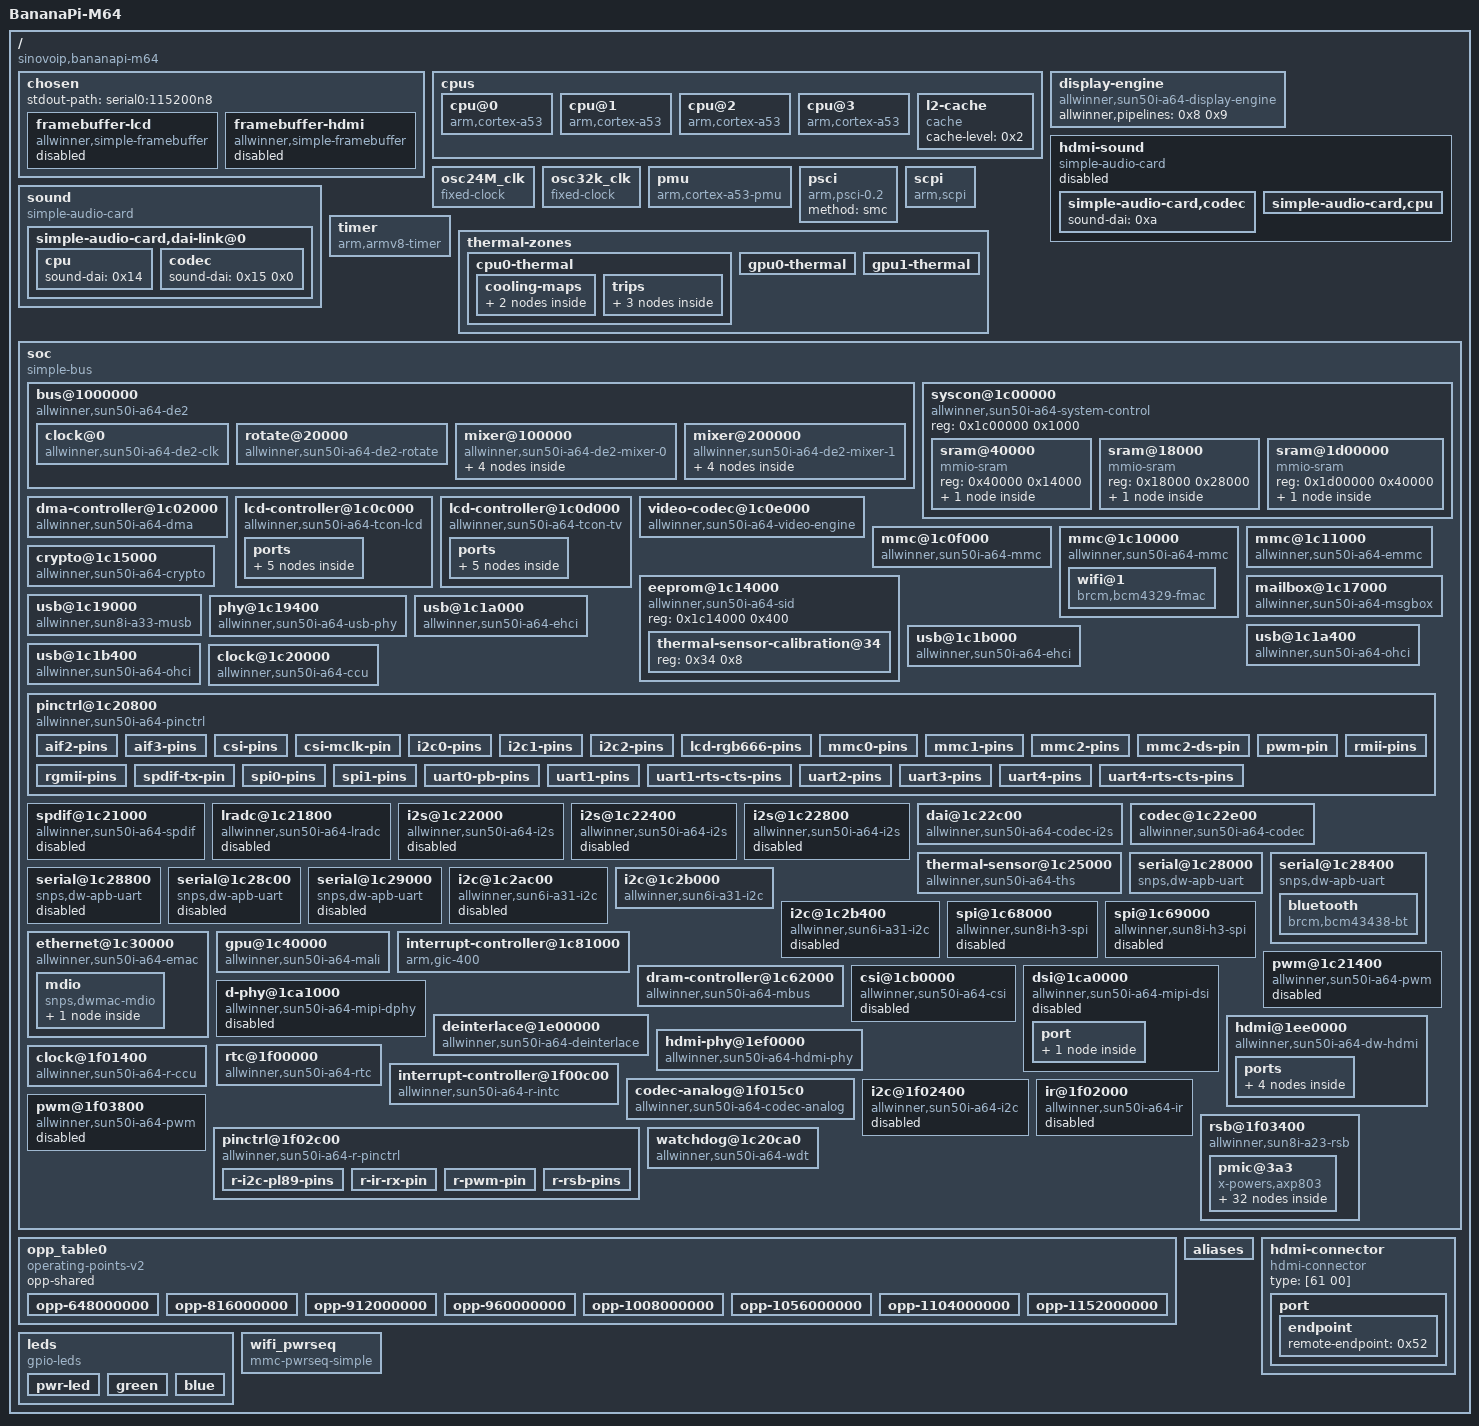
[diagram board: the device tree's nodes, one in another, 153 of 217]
/dts-v1/;

/ {
	interrupt-parent = <0x1>;
	#address-cells = <0x1>;
	#size-cells = <0x1>;
	model = "BananaPi-M64";
	compatible = "sinovoip,bananapi-m64", "allwinner,sun50i-a64";

	chosen {
		#address-cells = <0x1>;
		#size-cells = <0x1>;
		ranges;
		stdout-path = "serial0:115200n8";

		framebuffer-lcd {
			compatible = "allwinner,simple-framebuffer", "simple-framebuffer";
			allwinner,pipeline = "mixer0-lcd0";
			clocks = <0x2 0x64 0x3 0x6>;
			status = "disabled";
			phandle = <0x53>;
		};

		framebuffer-hdmi {
			compatible = "allwinner,simple-framebuffer", "simple-framebuffer";
			allwinner,pipeline = "mixer1-lcd1-hdmi";
			clocks = <0x3 0x7 0x2 0x65 0x2 0x6e>;
			status = "disabled";
			vcc-hdmi-supply = <0x4>;
			phandle = <0x54>;
		};
	};

	cpus {
		#address-cells = <0x1>;
		#size-cells = <0x0>;

		cpu@0 {
			compatible = "arm,cortex-a53";
			device_type = "cpu";
			reg = <0x0>;
			enable-method = "psci";
			next-level-cache = <0x5>;
			clocks = <0x2 0x15>;
			clock-names = "cpu";
			#cooling-cells = <0x2>;
			operating-points-v2 = <0x6>;
			cpu-supply = <0x7>;
			phandle = <0xc>;
		};

		cpu@1 {
			compatible = "arm,cortex-a53";
			device_type = "cpu";
			reg = <0x1>;
			enable-method = "psci";
			next-level-cache = <0x5>;
			clocks = <0x2 0x15>;
			clock-names = "cpu";
			#cooling-cells = <0x2>;
			operating-points-v2 = <0x6>;
			cpu-supply = <0x7>;
			phandle = <0xd>;
		};

		cpu@2 {
			compatible = "arm,cortex-a53";
			device_type = "cpu";
			reg = <0x2>;
			enable-method = "psci";
			next-level-cache = <0x5>;
			clocks = <0x2 0x15>;
			clock-names = "cpu";
			#cooling-cells = <0x2>;
			operating-points-v2 = <0x6>;
			cpu-supply = <0x7>;
			phandle = <0xe>;
		};

		cpu@3 {
			compatible = "arm,cortex-a53";
			device_type = "cpu";
			reg = <0x3>;
			enable-method = "psci";
			next-level-cache = <0x5>;
			clocks = <0x2 0x15>;
			clock-names = "cpu";
			#cooling-cells = <0x2>;
			operating-points-v2 = <0x6>;
			cpu-supply = <0x7>;
			phandle = <0xf>;
		};

		l2-cache {
			compatible = "cache";
			cache-level = <0x2>;
			phandle = <0x5>;
		};
	};

	display-engine {
		compatible = "allwinner,sun50i-a64-display-engine";
		allwinner,pipelines = <0x8 0x9>;
		status = "okay";
		phandle = <0x55>;
	};

	hdmi-sound {
		compatible = "simple-audio-card";
		simple-audio-card,format = "i2s";
		simple-audio-card,name = "sun50i-a64-hdmi";
		simple-audio-card,mclk-fs = <0x80>;
		simple-audio-card,frame-inversion;
		status = "disabled";
		phandle = <0x56>;

		simple-audio-card,codec {
			sound-dai = <0xa>;
		};

		simple-audio-card,cpu {
			sound-dai = <0xb>;
			dai-tdm-slot-num = <0x2>;
			dai-tdm-slot-width = <0x20>;
		};
	};

	osc24M_clk {
		#clock-cells = <0x0>;
		compatible = "fixed-clock";
		clock-frequency = <0x16e3600>;
		clock-output-names = "osc24M";
		phandle = <0x32>;
	};

	osc32k_clk {
		#clock-cells = <0x0>;
		compatible = "fixed-clock";
		clock-frequency = <0x8000>;
		clock-output-names = "ext-osc32k";
		phandle = <0x4c>;
	};

	pmu {
		compatible = "arm,cortex-a53-pmu";
		interrupts = <0x0 0x74 0x4 0x0 0x75 0x4 0x0 0x76 0x4 0x0 0x77 0x4>;
		interrupt-affinity = <0xc 0xd 0xe 0xf>;
	};

	psci {
		compatible = "arm,psci-0.2";
		method = "smc";
	};

	scpi {
		compatible = "arm,scpi";
		mboxes = <0x10 0x2 0x10 0x3>;
		mbox-names = "tx", "rx";
		shmem = <0x11>;
		phandle = <0x57>;
	};

	sound {
		#address-cells = <0x1>;
		#size-cells = <0x0>;
		compatible = "simple-audio-card";
		simple-audio-card,name = "sun50i-a64-audio";
		simple-audio-card,aux-devs = <0x12>;
		simple-audio-card,routing = "Headphone Jack", "HP", "Left DAC", "DAC Left", "Right DAC", "DAC Right", "ADC Left", "Left ADC", "ADC Right", "Right ADC", "MIC2", "Microphone Jack", "Onboard Microphone", "MBIAS", "MIC1", "Onboard Microphone";
		status = "okay";
		simple-audio-card,widgets = "Headphone", "Headphone Jack", "Microphone", "Microphone Jack", "Microphone", "Onboard Microphone";
		phandle = <0x58>;

		simple-audio-card,dai-link@0 {
			format = "i2s";
			frame-master = <0x13>;
			bitclock-master = <0x13>;
			mclk-fs = <0x80>;

			cpu {
				sound-dai = <0x14>;
				phandle = <0x13>;
			};

			codec {
				sound-dai = <0x15 0x0>;
				phandle = <0x59>;
			};
		};
	};

	timer {
		compatible = "arm,armv8-timer";
		allwinner,erratum-unknown1;
		arm,no-tick-in-suspend;
		interrupts = <0x1 0xd 0xf04 0x1 0xe 0xf04 0x1 0xb 0xf04 0x1 0xa 0xf04>;
	};

	thermal-zones {

		cpu0-thermal {
			polling-delay-passive = <0x0>;
			polling-delay = <0x0>;
			thermal-sensors = <0x16 0x0>;
			phandle = <0x5a>;

			cooling-maps {

				map0 {
					trip = <0x17>;
					cooling-device = <0xc 0xffffffff 0xffffffff 0xd 0xffffffff 0xffffffff 0xe 0xffffffff 0xffffffff 0xf 0xffffffff 0xffffffff>;
				};

				map1 {
					trip = <0x18>;
					cooling-device = <0xc 0xffffffff 0xffffffff 0xd 0xffffffff 0xffffffff 0xe 0xffffffff 0xffffffff 0xf 0xffffffff 0xffffffff>;
				};
			};

			trips {

				cpu_alert0 {
					temperature = <0x11170>;
					hysteresis = <0x7d0>;
					type = "passive";
					phandle = <0x17>;
				};

				cpu_alert1 {
					temperature = <0x13880>;
					hysteresis = <0x7d0>;
					type = "hot";
					phandle = <0x18>;
				};

				cpu_crit {
					temperature = <0x15f90>;
					hysteresis = <0x7d0>;
					type = "critical";
					phandle = <0x5b>;
				};
			};
		};

		gpu0-thermal {
			polling-delay-passive = <0x0>;
			polling-delay = <0x0>;
			thermal-sensors = <0x16 0x1>;
			phandle = <0x5c>;
		};

		gpu1-thermal {
			polling-delay-passive = <0x0>;
			polling-delay = <0x0>;
			thermal-sensors = <0x16 0x2>;
			phandle = <0x5d>;
		};
	};

	soc {
		compatible = "simple-bus";
		#address-cells = <0x1>;
		#size-cells = <0x1>;
		ranges;

		bus@1000000 {
			compatible = "allwinner,sun50i-a64-de2";
			reg = <0x1000000 0x400000>;
			allwinner,sram = <0x19 0x1>;
			#address-cells = <0x1>;
			#size-cells = <0x1>;
			ranges = <0x0 0x1000000 0x400000>;

			clock@0 {
				compatible = "allwinner,sun50i-a64-de2-clk";
				reg = <0x0 0x10000>;
				clocks = <0x2 0x34 0x2 0x63>;
				clock-names = "bus", "mod";
				resets = <0x2 0x1e>;
				#clock-cells = <0x1>;
				#reset-cells = <0x1>;
				phandle = <0x3>;
			};

			rotate@20000 {
				compatible = "allwinner,sun50i-a64-de2-rotate", "allwinner,sun8i-a83t-de2-rotate";
				reg = <0x20000 0x10000>;
				interrupts = <0x0 0x60 0x4>;
				clocks = <0x3 0x9 0x3 0xa>;
				clock-names = "bus", "mod";
				resets = <0x3 0x3>;
				phandle = <0x5e>;
			};

			mixer@100000 {
				compatible = "allwinner,sun50i-a64-de2-mixer-0";
				reg = <0x100000 0x100000>;
				clocks = <0x3 0x0 0x3 0x6>;
				clock-names = "bus", "mod";
				resets = <0x3 0x0>;
				phandle = <0x8>;

				ports {
					#address-cells = <0x1>;
					#size-cells = <0x0>;

					port@1 {
						#address-cells = <0x1>;
						#size-cells = <0x0>;
						reg = <0x1>;
						phandle = <0x5f>;

						endpoint@0 {
							reg = <0x0>;
							remote-endpoint = <0x1a>;
							phandle = <0x1e>;
						};

						endpoint@1 {
							reg = <0x1>;
							remote-endpoint = <0x1b>;
							phandle = <0x21>;
						};
					};
				};
			};

			mixer@200000 {
				compatible = "allwinner,sun50i-a64-de2-mixer-1";
				reg = <0x200000 0x100000>;
				clocks = <0x3 0x1 0x3 0x7>;
				clock-names = "bus", "mod";
				resets = <0x3 0x1>;
				phandle = <0x9>;

				ports {
					#address-cells = <0x1>;
					#size-cells = <0x0>;

					port@1 {
						#address-cells = <0x1>;
						#size-cells = <0x0>;
						reg = <0x1>;
						phandle = <0x60>;

						endpoint@0 {
							reg = <0x0>;
							remote-endpoint = <0x1c>;
							phandle = <0x1f>;
						};

						endpoint@1 {
							reg = <0x1>;
							remote-endpoint = <0x1d>;
							phandle = <0x22>;
						};
					};
				};
			};
		};

		syscon@1c00000 {
			compatible = "allwinner,sun50i-a64-system-control";
			reg = <0x1c00000 0x1000>;
			#address-cells = <0x1>;
			#size-cells = <0x1>;
			ranges;
			phandle = <0x3f>;

			sram@40000 {
				compatible = "mmio-sram";
				reg = <0x40000 0x14000>;
				#address-cells = <0x1>;
				#size-cells = <0x1>;
				ranges = <0x0 0x40000 0x14000>;
				phandle = <0x61>;

				scp-shmem@13c00 {
					compatible = "arm,scp-shmem";
					reg = <0x13c00 0x200>;
					phandle = <0x11>;
				};
			};

			sram@18000 {
				compatible = "mmio-sram";
				reg = <0x18000 0x28000>;
				#address-cells = <0x1>;
				#size-cells = <0x1>;
				ranges = <0x0 0x18000 0x28000>;
				phandle = <0x62>;

				sram-section@0 {
					compatible = "allwinner,sun50i-a64-sram-c";
					reg = <0x0 0x28000>;
					phandle = <0x19>;
				};
			};

			sram@1d00000 {
				compatible = "mmio-sram";
				reg = <0x1d00000 0x40000>;
				#address-cells = <0x1>;
				#size-cells = <0x1>;
				ranges = <0x0 0x1d00000 0x40000>;
				phandle = <0x63>;

				sram-section@0 {
					compatible = "allwinner,sun50i-a64-sram-c1", "allwinner,sun4i-a10-sram-c1";
					reg = <0x0 0x40000>;
					phandle = <0x24>;
				};
			};
		};

		dma-controller@1c02000 {
			compatible = "allwinner,sun50i-a64-dma";
			reg = <0x1c02000 0x1000>;
			interrupts = <0x0 0x32 0x4>;
			clocks = <0x2 0x1e>;
			dma-channels = <0x8>;
			dma-requests = <0x1b>;
			resets = <0x2 0x7>;
			#dma-cells = <0x1>;
			phandle = <0x34>;
		};

		lcd-controller@1c0c000 {
			compatible = "allwinner,sun50i-a64-tcon-lcd", "allwinner,sun8i-a83t-tcon-lcd";
			reg = <0x1c0c000 0x1000>;
			interrupts = <0x0 0x56 0x4>;
			clocks = <0x2 0x2f 0x2 0x64>;
			clock-names = "ahb", "tcon-ch0";
			clock-output-names = "tcon-pixel-clock";
			#clock-cells = <0x0>;
			resets = <0x2 0x18 0x2 0x23>;
			reset-names = "lcd", "lvds";
			phandle = <0x64>;

			ports {
				#address-cells = <0x1>;
				#size-cells = <0x0>;

				port@0 {
					#address-cells = <0x1>;
					#size-cells = <0x0>;
					reg = <0x0>;
					phandle = <0x65>;

					endpoint@0 {
						reg = <0x0>;
						remote-endpoint = <0x1e>;
						phandle = <0x1a>;
					};

					endpoint@1 {
						reg = <0x1>;
						remote-endpoint = <0x1f>;
						phandle = <0x1c>;
					};
				};

				port@1 {
					#address-cells = <0x1>;
					#size-cells = <0x0>;
					reg = <0x1>;
					phandle = <0x66>;

					endpoint@1 {
						reg = <0x1>;
						remote-endpoint = <0x20>;
						allwinner,tcon-channel = <0x1>;
						phandle = <0x46>;
					};
				};
			};
		};

		lcd-controller@1c0d000 {
			compatible = "allwinner,sun50i-a64-tcon-tv", "allwinner,sun8i-a83t-tcon-tv";
			reg = <0x1c0d000 0x1000>;
			interrupts = <0x0 0x57 0x4>;
			clocks = <0x2 0x30 0x2 0x65>;
			clock-names = "ahb", "tcon-ch1";
			resets = <0x2 0x19>;
			reset-names = "lcd";
			phandle = <0x67>;

			ports {
				#address-cells = <0x1>;
				#size-cells = <0x0>;

				port@0 {
					#address-cells = <0x1>;
					#size-cells = <0x0>;
					reg = <0x0>;
					phandle = <0x68>;

					endpoint@0 {
						reg = <0x0>;
						remote-endpoint = <0x21>;
						phandle = <0x1b>;
					};

					endpoint@1 {
						reg = <0x1>;
						remote-endpoint = <0x22>;
						phandle = <0x1d>;
					};
				};

				port@1 {
					#address-cells = <0x1>;
					#size-cells = <0x0>;
					reg = <0x1>;
					phandle = <0x69>;

					endpoint@1 {
						reg = <0x1>;
						remote-endpoint = <0x23>;
						phandle = <0x49>;
					};
				};
			};
		};

		video-codec@1c0e000 {
			compatible = "allwinner,sun50i-a64-video-engine";
			reg = <0x1c0e000 0x1000>;
			clocks = <0x2 0x2e 0x2 0x6a 0x2 0x5f>;
			clock-names = "ahb", "mod", "ram";
			resets = <0x2 0x17>;
			interrupts = <0x0 0x3a 0x4>;
			allwinner,sram = <0x24 0x1>;
		};

		mmc@1c0f000 {
			compatible = "allwinner,sun50i-a64-mmc";
			reg = <0x1c0f000 0x1000>;
			clocks = <0x2 0x1f 0x2 0x4b>;
			clock-names = "ahb", "mmc";
			resets = <0x2 0x8>;
			reset-names = "ahb";
			interrupts = <0x0 0x3c 0x4>;
			max-frequency = <0x8f0d180>;
			status = "okay";
			bus-width = <0x4>;
			#address-cells = <0x1>;
			#size-cells = <0x0>;
			pinctrl-names = "default";
			pinctrl-0 = <0x25>;
			vmmc-supply = <0x26>;
			cd-gpios = <0x27 0x5 0x6 0x1>;
			disable-wp;
			phandle = <0x6a>;
		};

		mmc@1c10000 {
			compatible = "allwinner,sun50i-a64-mmc";
			reg = <0x1c10000 0x1000>;
			clocks = <0x2 0x20 0x2 0x4c>;
			clock-names = "ahb", "mmc";
			resets = <0x2 0x9>;
			reset-names = "ahb";
			interrupts = <0x0 0x3d 0x4>;
			max-frequency = <0x8f0d180>;
			status = "okay";
			#address-cells = <0x1>;
			#size-cells = <0x0>;
			pinctrl-names = "default";
			pinctrl-0 = <0x28>;
			vmmc-supply = <0x29>;
			vqmmc-supply = <0x2a>;
			mmc-pwrseq = <0x2b>;
			bus-width = <0x4>;
			non-removable;
			phandle = <0x6b>;

			wifi@1 {
				reg = <0x1>;
				compatible = "brcm,bcm4329-fmac";
				interrupt-parent = <0x2c>;
				interrupts = <0x0 0x3 0x8>;
				interrupt-names = "host-wake";
				phandle = <0x6c>;
			};
		};

		mmc@1c11000 {
			compatible = "allwinner,sun50i-a64-emmc";
			reg = <0x1c11000 0x1000>;
			clocks = <0x2 0x21 0x2 0x4d>;
			clock-names = "ahb", "mmc";
			resets = <0x2 0xa>;
			reset-names = "ahb";
			interrupts = <0x0 0x3e 0x4>;
			max-frequency = <0xbebc200>;
			status = "okay";
			#address-cells = <0x1>;
			#size-cells = <0x0>;
			pinctrl-names = "default";
			pinctrl-0 = <0x2d 0x2e>;
			vmmc-supply = <0x26>;
			bus-width = <0x8>;
			non-removable;
			cap-mmc-hw-reset;
			phandle = <0x6d>;
		};

		eeprom@1c14000 {
			compatible = "allwinner,sun50i-a64-sid";
			reg = <0x1c14000 0x400>;
			#address-cells = <0x1>;
			#size-cells = <0x1>;
			phandle = <0x6e>;

			thermal-sensor-calibration@34 {
				reg = <0x34 0x8>;
				phandle = <0x36>;
			};
		};

		crypto@1c15000 {
			compatible = "allwinner,sun50i-a64-crypto";
			reg = <0x1c15000 0x1000>;
			interrupts = <0x0 0x5e 0x4>;
			clocks = <0x2 0x1d 0x2 0x4f>;
			clock-names = "bus", "mod";
			resets = <0x2 0x6>;
			phandle = <0x6f>;
		};

		mailbox@1c17000 {
			compatible = "allwinner,sun50i-a64-msgbox", "allwinner,sun6i-a31-msgbox";
			reg = <0x1c17000 0x1000>;
			clocks = <0x2 0x36>;
			resets = <0x2 0x20>;
			interrupts = <0x0 0x31 0x4>;
			#mbox-cells = <0x1>;
			phandle = <0x10>;
		};

		usb@1c19000 {
			compatible = "allwinner,sun8i-a33-musb";
			reg = <0x1c19000 0x400>;
			clocks = <0x2 0x29>;
			resets = <0x2 0x12>;
			interrupts = <0x0 0x47 0x4>;
			interrupt-names = "mc";
			phys = <0x2f 0x0>;
			phy-names = "usb";
			extcon = <0x2f 0x0>;
			dr_mode = "otg";
			status = "okay";
			phandle = <0x70>;
		};

		phy@1c19400 {
			compatible = "allwinner,sun50i-a64-usb-phy";
			reg = <0x1c19400 0x14 0x1c1a800 0x4 0x1c1b800 0x4>;
			reg-names = "phy_ctrl", "pmu0", "pmu1";
			clocks = <0x2 0x56 0x2 0x57>;
			clock-names = "usb0_phy", "usb1_phy";
			resets = <0x2 0x0 0x2 0x1>;
			reset-names = "usb0_reset", "usb1_reset";
			status = "okay";
			#phy-cells = <0x1>;
			usb0_id_det-gpios = <0x27 0x7 0x9 0x0>;
			usb0_vbus_power-supply = <0x30>;
			usb0_vbus-supply = <0x31>;
			phandle = <0x2f>;
		};

		usb@1c1a000 {
			compatible = "allwinner,sun50i-a64-ehci", "generic-ehci";
			reg = <0x1c1a000 0x100>;
			interrupts = <0x0 0x48 0x4>;
			clocks = <0x2 0x2c 0x2 0x2a 0x2 0x5b>;
			resets = <0x2 0x15 0x2 0x13>;
			status = "okay";
			phandle = <0x71>;
		};

		usb@1c1a400 {
			compatible = "allwinner,sun50i-a64-ohci", "generic-ohci";
			reg = <0x1c1a400 0x100>;
			interrupts = <0x0 0x49 0x4>;
			clocks = <0x2 0x2c 0x2 0x5b>;
			resets = <0x2 0x15>;
			status = "okay";
			phandle = <0x72>;
		};

		usb@1c1b000 {
			compatible = "allwinner,sun50i-a64-ehci", "generic-ehci";
			reg = <0x1c1b000 0x100>;
			interrupts = <0x0 0x4a 0x4>;
			clocks = <0x2 0x2d 0x2 0x2b 0x2 0x5d>;
			resets = <0x2 0x16 0x2 0x14>;
			phys = <0x2f 0x1>;
			phy-names = "usb";
			status = "okay";
			phandle = <0x73>;
		};

		usb@1c1b400 {
			compatible = "allwinner,sun50i-a64-ohci", "generic-ohci";
			reg = <0x1c1b400 0x100>;
			interrupts = <0x0 0x4b 0x4>;
			clocks = <0x2 0x2d 0x2 0x5d>;
			resets = <0x2 0x16>;
			phys = <0x2f 0x1>;
			phy-names = "usb";
			status = "okay";
			phandle = <0x74>;
		};

		clock@1c20000 {
			compatible = "allwinner,sun50i-a64-ccu";
			reg = <0x1c20000 0x400>;
			clocks = <0x32 0x33 0x0>;
			clock-names = "hosc", "losc";
			protected-clocks = <0x36>;
			#clock-cells = <0x1>;
			#reset-cells = <0x1>;
			phandle = <0x2>;
		};

		pinctrl@1c20800 {
			compatible = "allwinner,sun50i-a64-pinctrl";
			reg = <0x1c20800 0x400>;
			interrupts = <0x0 0xb 0x4 0x0 0x11 0x4 0x0 0x15 0x4>;
			clocks = <0x2 0x3a 0x32 0x33 0x0>;
			clock-names = "apb", "hosc", "losc";
			gpio-controller;
			#gpio-cells = <0x3>;
			interrupt-controller;
			#interrupt-cells = <0x3>;
			phandle = <0x27>;

			aif2-pins {
				pins = "PB4", "PB5", "PB6", "PB7";
				function = "aif2";
				phandle = <0x75>;
			};

			aif3-pins {
				pins = "PG10", "PG11", "PG12", "PG13";
				function = "aif3";
				phandle = <0x76>;
			};

			csi-pins {
				pins = "PE0", "PE2", "PE3", "PE4", "PE5", "PE6", "PE7", "PE8", "PE9", "PE10", "PE11";
				function = "csi";
				phandle = <0x44>;
			};

			csi-mclk-pin {
				pins = "PE1";
				function = "csi";
				phandle = <0x77>;
			};

			i2c0-pins {
				pins = "PH0", "PH1";
				function = "i2c0";
				phandle = <0x3a>;
			};

			i2c1-pins {
				pins = "PH2", "PH3";
				function = "i2c1";
				bias-pull-up;
				phandle = <0x3b>;
			};

			i2c2-pins {
				pins = "PE14", "PE15";
				function = "i2c2";
				phandle = <0x3c>;
			};

			lcd-rgb666-pins {
				pins = "PD0", "PD1", "PD2", "PD3", "PD4", "PD5", "PD6", "PD7", "PD8", "PD9", "PD10", "PD11", "PD12", "PD13", "PD14", "PD15", "PD16", "PD17", "PD18", "PD19", "PD20", "PD21";
				function = "lcd0";
				phandle = <0x78>;
			};

			mmc0-pins {
				pins = "PF0", "PF1", "PF2", "PF3", "PF4", "PF5";
				function = "mmc0";
				drive-strength = <0x1e>;
				bias-pull-up;
				phandle = <0x25>;
			};

			mmc1-pins {
				pins = "PG0", "PG1", "PG2", "PG3", "PG4", "PG5";
				function = "mmc1";
				drive-strength = <0x1e>;
				bias-pull-up;
				phandle = <0x28>;
			};

			mmc2-pins {
				pins = "PC5", "PC6", "PC8", "PC9", "PC10", "PC11", "PC12", "PC13", "PC14", "PC15", "PC16";
				function = "mmc2";
				drive-strength = <0x1e>;
				bias-pull-up;
				phandle = <0x2d>;
			};

			mmc2-ds-pin {
				pins = "PC1";
				function = "mmc2";
				drive-strength = <0x1e>;
				bias-pull-up;
				phandle = <0x2e>;
			};

			pwm-pin {
				pins = "PD22";
				function = "pwm";
				phandle = <0x43>;
			};

			rmii-pins {
				pins = "PD10", "PD11", "PD13", "PD14", "PD17", "PD18", "PD19", "PD20", "PD22", "PD23";
				function = "emac";
				drive-strength = <0x28>;
				phandle = <0x79>;
			};

			rgmii-pins {
				pins = "PD8", "PD9", "PD10", "PD11", "PD12", "PD13", "PD15", "PD16", "PD17", "PD18", "PD19", "PD20", "PD21", "PD22", "PD23";
				function = "emac";
				drive-strength = <0x28>;
				phandle = <0x40>;
			};

			spdif-tx-pin {
				pins = "PH8";
				function = "spdif";
				phandle = <0x35>;
			};

			spi0-pins {
				pins = "PC0", "PC1", "PC2", "PC3";
				function = "spi0";
				phandle = <0x3d>;
			};

			spi1-pins {
				pins = "PD0", "PD1", "PD2", "PD3";
				function = "spi1";
				phandle = <0x3e>;
			};

			uart0-pb-pins {
				pins = "PB8", "PB9";
				function = "uart0";
				phandle = <0x37>;
			};

			uart1-pins {
				pins = "PG6", "PG7";
				function = "uart1";
				phandle = <0x38>;
			};

			uart1-rts-cts-pins {
				pins = "PG8", "PG9";
				function = "uart1";
				phandle = <0x39>;
			};

			uart2-pins {
				pins = "PB0", "PB1";
				function = "uart2";
				phandle = <0x7a>;
			};

			uart3-pins {
				pins = "PD0", "PD1";
				function = "uart3";
				phandle = <0x7b>;
			};

			uart4-pins {
				pins = "PD2", "PD3";
				function = "uart4";
				phandle = <0x7c>;
			};

			uart4-rts-cts-pins {
				pins = "PD4", "PD5";
				function = "uart4";
				phandle = <0x7d>;
			};
		};

		spdif@1c21000 {
			#sound-dai-cells = <0x0>;
			compatible = "allwinner,sun50i-a64-spdif", "allwinner,sun8i-h3-spdif";
			reg = <0x1c21000 0x400>;
			interrupts = <0x0 0xc 0x4>;
			clocks = <0x2 0x39 0x2 0x55>;
			resets = <0x2 0x25>;
			clock-names = "apb", "spdif";
			dmas = <0x34 0x2>;
			dma-names = "tx";
			pinctrl-names = "default";
			pinctrl-0 = <0x35>;
			status = "disabled";
			phandle = <0x7e>;
		};

		lradc@1c21800 {
			compatible = "allwinner,sun50i-a64-lradc", "allwinner,sun4i-a10-lradc-keys";
			reg = <0x1c21800 0x400>;
			interrupts = <0x0 0x1e 0x4>;
			status = "disabled";
			phandle = <0x7f>;
		};

		i2s@1c22000 {
			#sound-dai-cells = <0x0>;
			compatible = "allwinner,sun50i-a64-i2s", "allwinner,sun8i-h3-i2s";
			reg = <0x1c22000 0x400>;
			interrupts = <0x0 0xd 0x4>;
			clocks = <0x2 0x3c 0x2 0x52>;
			clock-names = "apb", "mod";
			resets = <0x2 0x27>;
			dma-names = "rx", "tx";
			dmas = <0x34 0x3 0x34 0x3>;
			status = "disabled";
			phandle = <0x80>;
		};

		i2s@1c22400 {
			#sound-dai-cells = <0x0>;
			compatible = "allwinner,sun50i-a64-i2s", "allwinner,sun8i-h3-i2s";
			reg = <0x1c22400 0x400>;
			interrupts = <0x0 0xe 0x4>;
			clocks = <0x2 0x3d 0x2 0x53>;
			clock-names = "apb", "mod";
			resets = <0x2 0x28>;
			dma-names = "rx", "tx";
			dmas = <0x34 0x4 0x34 0x4>;
			status = "disabled";
			phandle = <0x81>;
		};

		i2s@1c22800 {
			#sound-dai-cells = <0x0>;
			compatible = "allwinner,sun50i-a64-i2s", "allwinner,sun8i-h3-i2s";
			reg = <0x1c22800 0x400>;
			interrupts = <0x0 0xf 0x4>;
			clocks = <0x2 0x3e 0x2 0x54>;
			clock-names = "apb", "mod";
			resets = <0x2 0x29>;
			dma-names = "tx";
			dmas = <0x34 0x1b>;
			allwinner,playback-channels = <0x8>;
			status = "disabled";
			phandle = <0xb>;
		};

		dai@1c22c00 {
			#sound-dai-cells = <0x0>;
			compatible = "allwinner,sun50i-a64-codec-i2s";
			reg = <0x1c22c00 0x200>;
			interrupts = <0x0 0x1d 0x4>;
			clocks = <0x2 0x38 0x2 0x6b>;
			clock-names = "apb", "mod";
			resets = <0x2 0x24>;
			dmas = <0x34 0xf 0x34 0xf>;
			dma-names = "rx", "tx";
			status = "okay";
			phandle = <0x14>;
		};

		codec@1c22e00 {
			#sound-dai-cells = <0x1>;
			compatible = "allwinner,sun50i-a64-codec";
			reg = <0x1c22e00 0x600>;
			interrupts = <0x0 0x1c 0x4>;
			clocks = <0x2 0x38 0x2 0x6b>;
			clock-names = "bus", "mod";
			status = "okay";
			phandle = <0x15>;
		};

		thermal-sensor@1c25000 {
			compatible = "allwinner,sun50i-a64-ths";
			reg = <0x1c25000 0x100>;
			clocks = <0x2 0x3b 0x2 0x49>;
			clock-names = "bus", "mod";
			interrupts = <0x0 0x1f 0x4>;
			resets = <0x2 0x26>;
			nvmem-cells = <0x36>;
			nvmem-cell-names = "calibration";
			#thermal-sensor-cells = <0x1>;
			phandle = <0x16>;
		};

		serial@1c28000 {
			compatible = "snps,dw-apb-uart";
			reg = <0x1c28000 0x400>;
			interrupts = <0x0 0x0 0x4>;
			reg-shift = <0x2>;
			reg-io-width = <0x4>;
			fifo-size = <0x40>;
			clocks = <0x2 0x43>;
			resets = <0x2 0x2e>;
			status = "okay";
			pinctrl-names = "default";
			pinctrl-0 = <0x37>;
			phandle = <0x82>;
		};

		serial@1c28400 {
			compatible = "snps,dw-apb-uart";
			reg = <0x1c28400 0x400>;
			interrupts = <0x0 0x1 0x4>;
			reg-shift = <0x2>;
			reg-io-width = <0x4>;
			fifo-size = <0x40>;
			clocks = <0x2 0x44>;
			resets = <0x2 0x2f>;
			status = "okay";
			pinctrl-names = "default";
			pinctrl-0 = <0x38 0x39>;
			uart-has-rtscts;
			phandle = <0x83>;

			bluetooth {
				compatible = "brcm,bcm43438-bt";
				clocks = <0x33 0x1>;
				clock-names = "lpo";
				vbat-supply = <0x29>;
				vddio-supply = <0x2a>;
				device-wakeup-gpios = <0x2c 0x0 0x6 0x0>;
				host-wakeup-gpios = <0x2c 0x0 0x5 0x0>;
				shutdown-gpios = <0x2c 0x0 0x4 0x0>;
			};
		};

		serial@1c28800 {
			compatible = "snps,dw-apb-uart";
			reg = <0x1c28800 0x400>;
			interrupts = <0x0 0x2 0x4>;
			reg-shift = <0x2>;
			reg-io-width = <0x4>;
			fifo-size = <0x40>;
			clocks = <0x2 0x45>;
			resets = <0x2 0x30>;
			status = "disabled";
			phandle = <0x84>;
		};

		serial@1c28c00 {
			compatible = "snps,dw-apb-uart";
			reg = <0x1c28c00 0x400>;
			interrupts = <0x0 0x3 0x4>;
			reg-shift = <0x2>;
			reg-io-width = <0x4>;
			fifo-size = <0x40>;
			clocks = <0x2 0x46>;
			resets = <0x2 0x31>;
			status = "disabled";
			phandle = <0x85>;
		};

		serial@1c29000 {
			compatible = "snps,dw-apb-uart";
			reg = <0x1c29000 0x400>;
			interrupts = <0x0 0x4 0x4>;
			reg-shift = <0x2>;
			reg-io-width = <0x4>;
			fifo-size = <0x40>;
			clocks = <0x2 0x47>;
			resets = <0x2 0x32>;
			status = "disabled";
			phandle = <0x86>;
		};

		i2c@1c2ac00 {
			compatible = "allwinner,sun6i-a31-i2c";
			reg = <0x1c2ac00 0x400>;
			interrupts = <0x0 0x6 0x4>;
			clocks = <0x2 0x3f>;
			resets = <0x2 0x2a>;
			pinctrl-names = "default";
			pinctrl-0 = <0x3a>;
			status = "disabled";
			#address-cells = <0x1>;
			#size-cells = <0x0>;
			phandle = <0x87>;
		};

		i2c@1c2b000 {
			compatible = "allwinner,sun6i-a31-i2c";
			reg = <0x1c2b000 0x400>;
			interrupts = <0x0 0x7 0x4>;
			clocks = <0x2 0x40>;
			resets = <0x2 0x2b>;
			pinctrl-names = "default";
			pinctrl-0 = <0x3b>;
			status = "okay";
			#address-cells = <0x1>;
			#size-cells = <0x0>;
			phandle = <0x88>;
		};

		i2c@1c2b400 {
			compatible = "allwinner,sun6i-a31-i2c";
			reg = <0x1c2b400 0x400>;
			interrupts = <0x0 0x8 0x4>;
			clocks = <0x2 0x41>;
			resets = <0x2 0x2c>;
			pinctrl-names = "default";
			pinctrl-0 = <0x3c>;
			status = "disabled";
			#address-cells = <0x1>;
			#size-cells = <0x0>;
			phandle = <0x89>;
		};

		spi@1c68000 {
			compatible = "allwinner,sun8i-h3-spi";
			reg = <0x1c68000 0x1000>;
			interrupts = <0x0 0x41 0x4>;
			clocks = <0x2 0x27 0x2 0x50>;
			clock-names = "ahb", "mod";
			dmas = <0x34 0x17 0x34 0x17>;
			dma-names = "rx", "tx";
			pinctrl-names = "default";
			pinctrl-0 = <0x3d>;
			resets = <0x2 0x10>;
			status = "disabled";
			num-cs = <0x1>;
			#address-cells = <0x1>;
			#size-cells = <0x0>;
			phandle = <0x8a>;
		};

		spi@1c69000 {
			compatible = "allwinner,sun8i-h3-spi";
			reg = <0x1c69000 0x1000>;
			interrupts = <0x0 0x42 0x4>;
			clocks = <0x2 0x28 0x2 0x51>;
			clock-names = "ahb", "mod";
			dmas = <0x34 0x18 0x34 0x18>;
			dma-names = "rx", "tx";
			pinctrl-names = "default";
			pinctrl-0 = <0x3e>;
			resets = <0x2 0x11>;
			status = "disabled";
			num-cs = <0x1>;
			#address-cells = <0x1>;
			#size-cells = <0x0>;
			phandle = <0x8b>;
		};

		ethernet@1c30000 {
			compatible = "allwinner,sun50i-a64-emac";
			syscon = <0x3f>;
			reg = <0x1c30000 0x10000>;
			interrupts = <0x0 0x52 0x4>;
			interrupt-names = "macirq";
			resets = <0x2 0xd>;
			reset-names = "stmmaceth";
			clocks = <0x2 0x24>;
			clock-names = "stmmaceth";
			status = "okay";
			pinctrl-names = "default";
			pinctrl-0 = <0x40>;
			phy-mode = "rgmii";
			phy-handle = <0x41>;
			phy-supply = <0x42>;
			phandle = <0x8c>;

			mdio {
				compatible = "snps,dwmac-mdio";
				#address-cells = <0x1>;
				#size-cells = <0x0>;
				phandle = <0x8d>;

				ethernet-phy@1 {
					compatible = "ethernet-phy-ieee802.3-c22";
					reg = <0x1>;
					phandle = <0x41>;
				};
			};
		};

		gpu@1c40000 {
			compatible = "allwinner,sun50i-a64-mali", "arm,mali-400";
			reg = <0x1c40000 0x10000>;
			interrupts = <0x0 0x61 0x4 0x0 0x62 0x4 0x0 0x63 0x4 0x0 0x64 0x4 0x0 0x66 0x4 0x0 0x67 0x4 0x0 0x65 0x4>;
			interrupt-names = "gp", "gpmmu", "pp0", "ppmmu0", "pp1", "ppmmu1", "pmu";
			clocks = <0x2 0x35 0x2 0x72>;
			clock-names = "bus", "core";
			resets = <0x2 0x1f>;
			phandle = <0x8e>;
		};

		interrupt-controller@1c81000 {
			compatible = "arm,gic-400";
			reg = <0x1c81000 0x1000 0x1c82000 0x2000 0x1c84000 0x2000 0x1c86000 0x2000>;
			interrupts = <0x1 0x9 0xf04>;
			interrupt-controller;
			#interrupt-cells = <0x3>;
			phandle = <0x1>;
		};

		pwm@1c21400 {
			compatible = "allwinner,sun50i-a64-pwm";
			reg = <0x1c21400 0x400>;
			clocks = <0x32>;
			pinctrl-names = "default";
			pinctrl-0 = <0x43>;
			#pwm-cells = <0x3>;
			status = "disabled";
			phandle = <0x8f>;
		};

		dram-controller@1c62000 {
			compatible = "allwinner,sun50i-a64-mbus";
			reg = <0x1c62000 0x1000>;
			clocks = <0x2 0x70>;
			#address-cells = <0x1>;
			#size-cells = <0x1>;
			dma-ranges = <0x0 0x40000000 0xc0000000>;
			#interconnect-cells = <0x1>;
			phandle = <0x47>;
		};

		csi@1cb0000 {
			compatible = "allwinner,sun50i-a64-csi";
			reg = <0x1cb0000 0x1000>;
			interrupts = <0x0 0x54 0x4>;
			clocks = <0x2 0x32 0x2 0x68 0x2 0x60>;
			clock-names = "bus", "mod", "ram";
			resets = <0x2 0x1b>;
			pinctrl-names = "default";
			pinctrl-0 = <0x44>;
			status = "disabled";
			phandle = <0x90>;
		};

		dsi@1ca0000 {
			compatible = "allwinner,sun50i-a64-mipi-dsi";
			reg = <0x1ca0000 0x1000>;
			interrupts = <0x0 0x59 0x4>;
			clocks = <0x2 0x1c>;
			resets = <0x2 0x5>;
			phys = <0x45>;
			phy-names = "dphy";
			status = "disabled";
			#address-cells = <0x1>;
			#size-cells = <0x0>;
			phandle = <0x91>;

			port {

				endpoint {
					remote-endpoint = <0x46>;
					phandle = <0x20>;
				};
			};
		};

		d-phy@1ca1000 {
			compatible = "allwinner,sun50i-a64-mipi-dphy", "allwinner,sun6i-a31-mipi-dphy";
			reg = <0x1ca1000 0x1000>;
			clocks = <0x2 0x1c 0x2 0x71>;
			clock-names = "bus", "mod";
			resets = <0x2 0x5>;
			status = "disabled";
			#phy-cells = <0x0>;
			phandle = <0x45>;
		};

		deinterlace@1e00000 {
			compatible = "allwinner,sun50i-a64-deinterlace", "allwinner,sun8i-h3-deinterlace";
			reg = <0x1e00000 0x20000>;
			clocks = <0x2 0x31 0x2 0x66 0x2 0x61>;
			clock-names = "bus", "mod", "ram";
			resets = <0x2 0x1a>;
			interrupts = <0x0 0x5d 0x4>;
			interconnects = <0x47 0x9>;
			interconnect-names = "dma-mem";
			phandle = <0x92>;
		};

		hdmi@1ee0000 {
			#sound-dai-cells = <0x0>;
			compatible = "allwinner,sun50i-a64-dw-hdmi", "allwinner,sun8i-a83t-dw-hdmi";
			reg = <0x1ee0000 0x10000>;
			reg-io-width = <0x1>;
			interrupts = <0x0 0x58 0x4>;
			clocks = <0x2 0x33 0x2 0x6f 0x2 0x6e>;
			clock-names = "iahb", "isfr", "tmds";
			resets = <0x2 0x1d>;
			reset-names = "ctrl";
			phys = <0x48>;
			phy-names = "phy";
			status = "okay";
			hvcc-supply = <0x4>;
			phandle = <0xa>;

			ports {
				#address-cells = <0x1>;
				#size-cells = <0x0>;

				port@0 {
					reg = <0x0>;
					phandle = <0x93>;

					endpoint {
						remote-endpoint = <0x49>;
						phandle = <0x23>;
					};
				};

				port@1 {
					reg = <0x1>;
					phandle = <0x94>;

					endpoint {
						remote-endpoint = <0x4a>;
						phandle = <0x52>;
					};
				};
			};
		};

		hdmi-phy@1ef0000 {
			compatible = "allwinner,sun50i-a64-hdmi-phy";
			reg = <0x1ef0000 0x10000>;
			clocks = <0x2 0x33 0x2 0x6f 0x2 0x7>;
			clock-names = "bus", "mod", "pll-0";
			resets = <0x2 0x1c>;
			reset-names = "phy";
			#phy-cells = <0x0>;
			phandle = <0x48>;
		};

		rtc@1f00000 {
			compatible = "allwinner,sun50i-a64-rtc", "allwinner,sun8i-h3-rtc";
			reg = <0x1f00000 0x400>;
			interrupt-parent = <0x4b>;
			interrupts = <0x8 0x4 0x9 0x4>;
			clock-output-names = "osc32k", "osc32k-out", "iosc";
			clocks = <0x4c>;
			#clock-cells = <0x1>;
			phandle = <0x33>;
		};

		interrupt-controller@1f00c00 {
			compatible = "allwinner,sun50i-a64-r-intc", "allwinner,sun6i-a31-r-intc";
			interrupt-controller;
			#interrupt-cells = <0x2>;
			reg = <0x1f00c00 0x400>;
			interrupts = <0x0 0x20 0x4>;
			phandle = <0x4b>;
		};

		clock@1f01400 {
			compatible = "allwinner,sun50i-a64-r-ccu";
			reg = <0x1f01400 0x100>;
			clocks = <0x32 0x33 0x0 0x33 0x2 0x2 0xb>;
			clock-names = "hosc", "losc", "iosc", "pll-periph";
			protected-clocks = <0xa>;
			#clock-cells = <0x1>;
			#reset-cells = <0x1>;
			phandle = <0x4e>;
		};

		codec-analog@1f015c0 {
			compatible = "allwinner,sun50i-a64-codec-analog";
			reg = <0x1f015c0 0x4>;
			allwinner,codec = <0x15>;
			status = "okay";
			cpvdd-supply = <0x4d>;
			phandle = <0x12>;
		};

		i2c@1f02400 {
			compatible = "allwinner,sun50i-a64-i2c", "allwinner,sun6i-a31-i2c";
			reg = <0x1f02400 0x400>;
			interrupts = <0x0 0x2c 0x4>;
			clocks = <0x4e 0x9>;
			resets = <0x4e 0x5>;
			status = "disabled";
			#address-cells = <0x1>;
			#size-cells = <0x0>;
			phandle = <0x95>;
		};

		ir@1f02000 {
			compatible = "allwinner,sun50i-a64-ir", "allwinner,sun6i-a31-ir";
			reg = <0x1f02000 0x400>;
			clocks = <0x4e 0x4 0x4e 0xb>;
			clock-names = "apb", "ir";
			resets = <0x4e 0x0>;
			interrupt-parent = <0x4b>;
			interrupts = <0x5 0x4>;
			pinctrl-names = "default";
			pinctrl-0 = <0x4f>;
			status = "disabled";
			phandle = <0x96>;
		};

		pwm@1f03800 {
			compatible = "allwinner,sun50i-a64-pwm";
			reg = <0x1f03800 0x400>;
			clocks = <0x32>;
			pinctrl-names = "default";
			pinctrl-0 = <0x50>;
			#pwm-cells = <0x3>;
			status = "disabled";
			phandle = <0x97>;
		};

		pinctrl@1f02c00 {
			compatible = "allwinner,sun50i-a64-r-pinctrl";
			reg = <0x1f02c00 0x400>;
			interrupt-parent = <0x4b>;
			interrupts = <0xd 0x4>;
			clocks = <0x4e 0x3 0x32 0x4c>;
			clock-names = "apb", "hosc", "losc";
			gpio-controller;
			#gpio-cells = <0x3>;
			interrupt-controller;
			#interrupt-cells = <0x3>;
			phandle = <0x2c>;

			r-i2c-pl89-pins {
				pins = "PL8", "PL9";
				function = "s_i2c";
				phandle = <0x98>;
			};

			r-ir-rx-pin {
				pins = "PL11";
				function = "s_cir_rx";
				phandle = <0x4f>;
			};

			r-pwm-pin {
				pins = "PL10";
				function = "s_pwm";
				phandle = <0x50>;
			};

			r-rsb-pins {
				pins = "PL0", "PL1";
				function = "s_rsb";
				phandle = <0x51>;
			};
		};

		rsb@1f03400 {
			compatible = "allwinner,sun8i-a23-rsb";
			reg = <0x1f03400 0x400>;
			interrupts = <0x0 0x27 0x4>;
			clocks = <0x4e 0x6>;
			clock-frequency = <0x2dc6c0>;
			resets = <0x4e 0x2>;
			pinctrl-names = "default";
			pinctrl-0 = <0x51>;
			status = "okay";
			#address-cells = <0x1>;
			#size-cells = <0x0>;
			phandle = <0x99>;

			pmic@3a3 {
				compatible = "x-powers,axp803";
				reg = <0x3a3>;
				interrupt-parent = <0x4b>;
				interrupts = <0x0 0x8>;
				x-powers,drive-vbus-en;
				interrupt-controller;
				#interrupt-cells = <0x1>;
				phandle = <0x9a>;

				ac-power-supply {
					compatible = "x-powers,axp803-ac-power-supply", "x-powers,axp813-ac-power-supply";
					status = "okay";
					phandle = <0x9b>;
				};

				adc {
					compatible = "x-powers,axp803-adc", "x-powers,axp813-adc";
					#io-channel-cells = <0x1>;
					#thermal-sensor-cells = <0x0>;
					phandle = <0x9c>;
				};

				gpio {
					compatible = "x-powers,axp803-gpio", "x-powers,axp813-gpio";
					gpio-controller;
					#gpio-cells = <0x2>;
					phandle = <0x9d>;

					gpio0-ldo {
						pins = "GPIO0";
						function = "ldo";
						phandle = <0x9e>;
					};

					gpio1-ldo {
						pins = "GPIO1";
						function = "ldo";
						phandle = <0x9f>;
					};
				};

				led {
					compatible = "x-powers,axp20x-led";
					status = "disabled";
					phandle = <0xa0>;
				};

				battery-power-supply {
					compatible = "x-powers,axp803-battery-power-supply", "x-powers,axp813-battery-power-supply";
					status = "okay";
					phandle = <0xa1>;
				};

				regulators {
					x-powers,dcdc-freq = <0xbb8>;

					aldo1 {
						regulator-name = "afvcc-csi";
						regulator-always-on;
						regulator-min-microvolt = <0x2ab980>;
						regulator-max-microvolt = <0x2ab980>;
						phandle = <0xa2>;
					};

					aldo2 {
						regulator-name = "vcc-pl";
						regulator-always-on;
						regulator-min-microvolt = <0x1b7740>;
						regulator-max-microvolt = <0x325aa0>;
						phandle = <0xa3>;
					};

					aldo3 {
						regulator-name = "vcc-pll-avcc";
						regulator-always-on;
						regulator-min-microvolt = <0x2dc6c0>;
						regulator-max-microvolt = <0x2dc6c0>;
						phandle = <0xa4>;
					};

					dc1sw {
						regulator-name = "vcc-phy";
						regulator-always-on;
						phandle = <0x42>;
					};

					dcdc1 {
						regulator-name = "vcc-3v3";
						regulator-always-on;
						regulator-min-microvolt = <0x325aa0>;
						regulator-max-microvolt = <0x325aa0>;
						phandle = <0x26>;
					};

					dcdc2 {
						regulator-name = "vdd-cpux";
						regulator-always-on;
						regulator-min-microvolt = <0xfde80>;
						regulator-max-microvolt = <0x13d620>;
						phandle = <0x7>;
					};

					dcdc3 {
						regulator-name = "dcdc3";
						phandle = <0xa5>;
					};

					dcdc4 {
						regulator-name = "dcdc4";
						phandle = <0xa6>;
					};

					dcdc5 {
						regulator-name = "vcc-dram";
						regulator-always-on;
						regulator-min-microvolt = <0x16e360>;
						regulator-max-microvolt = <0x16e360>;
						phandle = <0xa7>;
					};

					dcdc6 {
						regulator-name = "vdd-sys";
						regulator-always-on;
						regulator-min-microvolt = <0x10c8e0>;
						regulator-max-microvolt = <0x10c8e0>;
						phandle = <0xa8>;
					};

					dldo1 {
						regulator-name = "vcc-hdmi-dsi";
						regulator-min-microvolt = <0x325aa0>;
						regulator-max-microvolt = <0x325aa0>;
						phandle = <0x4>;
					};

					dldo2 {
						regulator-name = "vcc-wifi";
						regulator-min-microvolt = <0x325aa0>;
						regulator-max-microvolt = <0x325aa0>;
						phandle = <0x29>;
					};

					dldo3 {
						regulator-name = "dldo3";
						phandle = <0xa9>;
					};

					dldo4 {
						regulator-name = "vcc-wifi-io";
						regulator-min-microvolt = <0x1b7740>;
						regulator-max-microvolt = <0x325aa0>;
						phandle = <0x2a>;
					};

					eldo1 {
						regulator-name = "cpvdd";
						regulator-min-microvolt = <0x1b7740>;
						regulator-max-microvolt = <0x1b7740>;
						phandle = <0x4d>;
					};

					eldo2 {
						regulator-name = "eldo2";
						phandle = <0xaa>;
					};

					eldo3 {
						regulator-name = "eldo3";
						phandle = <0xab>;
					};

					fldo1 {
						regulator-name = "vcc-1v2-hsic";
						regulator-min-microvolt = <0x124f80>;
						regulator-max-microvolt = <0x124f80>;
						phandle = <0xac>;
					};

					fldo2 {
						regulator-name = "vdd-cpus";
						regulator-always-on;
						regulator-min-microvolt = <0x10c8e0>;
						regulator-max-microvolt = <0x10c8e0>;
						phandle = <0xad>;
					};

					ldo-io0 {
						regulator-name = "ldo-io0";
						status = "disabled";
						phandle = <0xae>;
					};

					ldo-io1 {
						regulator-name = "ldo-io1";
						status = "disabled";
						phandle = <0xaf>;
					};

					rtc-ldo {
						regulator-always-on;
						regulator-min-microvolt = <0x2dc6c0>;
						regulator-max-microvolt = <0x2dc6c0>;
						regulator-name = "vcc-rtc";
						phandle = <0xb0>;
					};

					drivevbus {
						regulator-name = "usb0-vbus";
						status = "okay";
						phandle = <0x31>;
					};
				};

				usb-power-supply {
					compatible = "x-powers,axp803-usb-power-supply", "x-powers,axp813-usb-power-supply";
					status = "okay";
					phandle = <0x30>;
				};
			};
		};

		watchdog@1c20ca0 {
			compatible = "allwinner,sun50i-a64-wdt", "allwinner,sun6i-a31-wdt";
			reg = <0x1c20ca0 0x20>;
			interrupts = <0x0 0x19 0x4>;
			clocks = <0x32>;
			phandle = <0xb1>;
		};
	};

	opp_table0 {
		compatible = "operating-points-v2";
		opp-shared;
		phandle = <0x6>;

		opp-648000000 {
			opp-hz = <0x0 0x269fb200>;
			opp-microvolt = <0xfde80>;
			clock-latency-ns = <0x3b9b0>;
		};

		opp-816000000 {
			opp-hz = <0x0 0x30a32c00>;
			opp-microvolt = <0x10c8e0>;
			clock-latency-ns = <0x3b9b0>;
		};

		opp-912000000 {
			opp-hz = <0x0 0x365c0400>;
			opp-microvolt = <0x111700>;
			clock-latency-ns = <0x3b9b0>;
		};

		opp-960000000 {
			opp-hz = <0x0 0x39387000>;
			opp-microvolt = <0x11b340>;
			clock-latency-ns = <0x3b9b0>;
		};

		opp-1008000000 {
			opp-hz = <0x0 0x3c14dc00>;
			opp-microvolt = <0x124f80>;
			clock-latency-ns = <0x3b9b0>;
		};

		opp-1056000000 {
			opp-hz = <0x0 0x3ef14800>;
			opp-microvolt = <0x12ebc0>;
			clock-latency-ns = <0x3b9b0>;
		};

		opp-1104000000 {
			opp-hz = <0x0 0x41cdb400>;
			opp-microvolt = <0x1339e0>;
			clock-latency-ns = <0x3b9b0>;
		};

		opp-1152000000 {
			opp-hz = <0x0 0x44aa2000>;
			opp-microvolt = <0x13d620>;
			clock-latency-ns = <0x3b9b0>;
		};
	};

	aliases {
		ethernet0 = "/soc/ethernet@1c30000";
		serial0 = "/soc/serial@1c28000";
		serial1 = "/soc/serial@1c28400";
	};

	hdmi-connector {
		compatible = "hdmi-connector";
		type = [61 00];

		port {

			endpoint {
				remote-endpoint = <0x52>;
				phandle = <0x4a>;
			};
		};
	};

	leds {
		compatible = "gpio-leds";

		pwr-led {
			label = "bananapi-m64:red:pwr";
			gpios = <0x27 0x3 0x18 0x0>;
			default-state = "on";
		};

		green {
			label = "bananapi-m64:green:user";
			gpios = <0x27 0x4 0xe 0x0>;
		};

		blue {
			label = "bananapi-m64:blue:user";
			gpios = <0x27 0x4 0xf 0x0>;
		};
	};

	wifi_pwrseq {
		compatible = "mmc-pwrseq-simple";
		reset-gpios = <0x2c 0x0 0x2 0x1>;
		clocks = <0x33 0x1>;
		clock-names = "ext_clock";
		phandle = <0x2b>;
	};

	__symbols__ {
		simplefb_lcd = "/chosen/framebuffer-lcd";
		simplefb_hdmi = "/chosen/framebuffer-hdmi";
		cpu0 = "/cpus/cpu@0";
		cpu1 = "/cpus/cpu@1";
		cpu2 = "/cpus/cpu@2";
		cpu3 = "/cpus/cpu@3";
		L2 = "/cpus/l2-cache";
		de = "/display-engine";
		hdmi_sound = "/hdmi-sound";
		osc24M = "/osc24M_clk";
		osc32k = "/osc32k_clk";
		scpi_protocol = "/scpi";
		sound = "/sound";
		link0_cpu = "/sound/simple-audio-card,dai-link@0/cpu";
		link0_codec = "/sound/simple-audio-card,dai-link@0/codec";
		cpu_thermal = "/thermal-zones/cpu0-thermal";
		cpu_alert0 = "/thermal-zones/cpu0-thermal/trips/cpu_alert0";
		cpu_alert1 = "/thermal-zones/cpu0-thermal/trips/cpu_alert1";
		cpu_crit = "/thermal-zones/cpu0-thermal/trips/cpu_crit";
		gpu0_thermal = "/thermal-zones/gpu0-thermal";
		gpu1_thermal = "/thermal-zones/gpu1-thermal";
		display_clocks = "/soc/bus@1000000/clock@0";
		rotate = "/soc/bus@1000000/rotate@20000";
		mixer0 = "/soc/bus@1000000/mixer@100000";
		mixer0_out = "/soc/bus@1000000/mixer@100000/ports/port@1";
		mixer0_out_tcon0 = "/soc/bus@1000000/mixer@100000/ports/port@1/endpoint@0";
		mixer0_out_tcon1 = "/soc/bus@1000000/mixer@100000/ports/port@1/endpoint@1";
		mixer1 = "/soc/bus@1000000/mixer@200000";
		mixer1_out = "/soc/bus@1000000/mixer@200000/ports/port@1";
		mixer1_out_tcon0 = "/soc/bus@1000000/mixer@200000/ports/port@1/endpoint@0";
		mixer1_out_tcon1 = "/soc/bus@1000000/mixer@200000/ports/port@1/endpoint@1";
		syscon = "/soc/syscon@1c00000";
		sram_a2 = "/soc/syscon@1c00000/sram@40000";
		scpi_sram = "/soc/syscon@1c00000/sram@40000/scp-shmem@13c00";
		sram_c = "/soc/syscon@1c00000/sram@18000";
		de2_sram = "/soc/syscon@1c00000/sram@18000/sram-section@0";
		sram_c1 = "/soc/syscon@1c00000/sram@1d00000";
		ve_sram = "/soc/syscon@1c00000/sram@1d00000/sram-section@0";
		dma = "/soc/dma-controller@1c02000";
		tcon0 = "/soc/lcd-controller@1c0c000";
		tcon0_in = "/soc/lcd-controller@1c0c000/ports/port@0";
		tcon0_in_mixer0 = "/soc/lcd-controller@1c0c000/ports/port@0/endpoint@0";
		tcon0_in_mixer1 = "/soc/lcd-controller@1c0c000/ports/port@0/endpoint@1";
		tcon0_out = "/soc/lcd-controller@1c0c000/ports/port@1";
		tcon0_out_dsi = "/soc/lcd-controller@1c0c000/ports/port@1/endpoint@1";
		tcon1 = "/soc/lcd-controller@1c0d000";
		tcon1_in = "/soc/lcd-controller@1c0d000/ports/port@0";
		tcon1_in_mixer0 = "/soc/lcd-controller@1c0d000/ports/port@0/endpoint@0";
		tcon1_in_mixer1 = "/soc/lcd-controller@1c0d000/ports/port@0/endpoint@1";
		tcon1_out = "/soc/lcd-controller@1c0d000/ports/port@1";
		tcon1_out_hdmi = "/soc/lcd-controller@1c0d000/ports/port@1/endpoint@1";
		mmc0 = "/soc/mmc@1c0f000";
		mmc1 = "/soc/mmc@1c10000";
		brcmf = "/soc/mmc@1c10000/wifi@1";
		mmc2 = "/soc/mmc@1c11000";
		sid = "/soc/eeprom@1c14000";
		ths_calibration = "/soc/eeprom@1c14000/thermal-sensor-calibration@34";
		crypto = "/soc/crypto@1c15000";
		msgbox = "/soc/mailbox@1c17000";
		usb_otg = "/soc/usb@1c19000";
		usbphy = "/soc/phy@1c19400";
		ehci0 = "/soc/usb@1c1a000";
		ohci0 = "/soc/usb@1c1a400";
		ehci1 = "/soc/usb@1c1b000";
		ohci1 = "/soc/usb@1c1b400";
		ccu = "/soc/clock@1c20000";
		pio = "/soc/pinctrl@1c20800";
		aif2_pins = "/soc/pinctrl@1c20800/aif2-pins";
		aif3_pins = "/soc/pinctrl@1c20800/aif3-pins";
		csi_pins = "/soc/pinctrl@1c20800/csi-pins";
		csi_mclk_pin = "/soc/pinctrl@1c20800/csi-mclk-pin";
		i2c0_pins = "/soc/pinctrl@1c20800/i2c0-pins";
		i2c1_pins = "/soc/pinctrl@1c20800/i2c1-pins";
		i2c2_pins = "/soc/pinctrl@1c20800/i2c2-pins";
		lcd_rgb666_pins = "/soc/pinctrl@1c20800/lcd-rgb666-pins";
		mmc0_pins = "/soc/pinctrl@1c20800/mmc0-pins";
		mmc1_pins = "/soc/pinctrl@1c20800/mmc1-pins";
		mmc2_pins = "/soc/pinctrl@1c20800/mmc2-pins";
		mmc2_ds_pin = "/soc/pinctrl@1c20800/mmc2-ds-pin";
		pwm_pin = "/soc/pinctrl@1c20800/pwm-pin";
		rmii_pins = "/soc/pinctrl@1c20800/rmii-pins";
		rgmii_pins = "/soc/pinctrl@1c20800/rgmii-pins";
		spdif_tx_pin = "/soc/pinctrl@1c20800/spdif-tx-pin";
		spi0_pins = "/soc/pinctrl@1c20800/spi0-pins";
		spi1_pins = "/soc/pinctrl@1c20800/spi1-pins";
		uart0_pb_pins = "/soc/pinctrl@1c20800/uart0-pb-pins";
		uart1_pins = "/soc/pinctrl@1c20800/uart1-pins";
		uart1_rts_cts_pins = "/soc/pinctrl@1c20800/uart1-rts-cts-pins";
		uart2_pins = "/soc/pinctrl@1c20800/uart2-pins";
		uart3_pins = "/soc/pinctrl@1c20800/uart3-pins";
		uart4_pins = "/soc/pinctrl@1c20800/uart4-pins";
		uart4_rts_cts_pins = "/soc/pinctrl@1c20800/uart4-rts-cts-pins";
		spdif = "/soc/spdif@1c21000";
		lradc = "/soc/lradc@1c21800";
		i2s0 = "/soc/i2s@1c22000";
		i2s1 = "/soc/i2s@1c22400";
		i2s2 = "/soc/i2s@1c22800";
		dai = "/soc/dai@1c22c00";
		codec = "/soc/codec@1c22e00";
		ths = "/soc/thermal-sensor@1c25000";
		uart0 = "/soc/serial@1c28000";
		uart1 = "/soc/serial@1c28400";
		uart2 = "/soc/serial@1c28800";
		uart3 = "/soc/serial@1c28c00";
		uart4 = "/soc/serial@1c29000";
		i2c0 = "/soc/i2c@1c2ac00";
		i2c1 = "/soc/i2c@1c2b000";
		i2c2 = "/soc/i2c@1c2b400";
		spi0 = "/soc/spi@1c68000";
		spi1 = "/soc/spi@1c69000";
		emac = "/soc/ethernet@1c30000";
		mdio = "/soc/ethernet@1c30000/mdio";
		ext_rgmii_phy = "/soc/ethernet@1c30000/mdio/ethernet-phy@1";
		mali = "/soc/gpu@1c40000";
		gic = "/soc/interrupt-controller@1c81000";
		pwm = "/soc/pwm@1c21400";
		mbus = "/soc/dram-controller@1c62000";
		csi = "/soc/csi@1cb0000";
		dsi = "/soc/dsi@1ca0000";
		dsi_in_tcon0 = "/soc/dsi@1ca0000/port/endpoint";
		dphy = "/soc/d-phy@1ca1000";
		deinterlace = "/soc/deinterlace@1e00000";
		hdmi = "/soc/hdmi@1ee0000";
		hdmi_in = "/soc/hdmi@1ee0000/ports/port@0";
		hdmi_in_tcon1 = "/soc/hdmi@1ee0000/ports/port@0/endpoint";
		hdmi_out = "/soc/hdmi@1ee0000/ports/port@1";
		hdmi_out_con = "/soc/hdmi@1ee0000/ports/port@1/endpoint";
		hdmi_phy = "/soc/hdmi-phy@1ef0000";
		rtc = "/soc/rtc@1f00000";
		r_intc = "/soc/interrupt-controller@1f00c00";
		r_ccu = "/soc/clock@1f01400";
		codec_analog = "/soc/codec-analog@1f015c0";
		r_i2c = "/soc/i2c@1f02400";
		r_ir = "/soc/ir@1f02000";
		r_pwm = "/soc/pwm@1f03800";
		r_pio = "/soc/pinctrl@1f02c00";
		r_i2c_pl89_pins = "/soc/pinctrl@1f02c00/r-i2c-pl89-pins";
		r_ir_rx_pin = "/soc/pinctrl@1f02c00/r-ir-rx-pin";
		r_pwm_pin = "/soc/pinctrl@1f02c00/r-pwm-pin";
		r_rsb_pins = "/soc/pinctrl@1f02c00/r-rsb-pins";
		r_rsb = "/soc/rsb@1f03400";
		axp803 = "/soc/rsb@1f03400/pmic@3a3";
		ac_power_supply = "/soc/rsb@1f03400/pmic@3a3/ac-power-supply";
		axp_adc = "/soc/rsb@1f03400/pmic@3a3/adc";
		axp_gpio = "/soc/rsb@1f03400/pmic@3a3/gpio";
		gpio0_ldo = "/soc/rsb@1f03400/pmic@3a3/gpio/gpio0-ldo";
		gpio1_ldo = "/soc/rsb@1f03400/pmic@3a3/gpio/gpio1-ldo";
		axp_led = "/soc/rsb@1f03400/pmic@3a3/led";
		battery_power_supply = "/soc/rsb@1f03400/pmic@3a3/battery-power-supply";
		reg_aldo1 = "/soc/rsb@1f03400/pmic@3a3/regulators/aldo1";
		reg_aldo2 = "/soc/rsb@1f03400/pmic@3a3/regulators/aldo2";
		reg_aldo3 = "/soc/rsb@1f03400/pmic@3a3/regulators/aldo3";
		reg_dc1sw = "/soc/rsb@1f03400/pmic@3a3/regulators/dc1sw";
		reg_dcdc1 = "/soc/rsb@1f03400/pmic@3a3/regulators/dcdc1";
		reg_dcdc2 = "/soc/rsb@1f03400/pmic@3a3/regulators/dcdc2";
		reg_dcdc3 = "/soc/rsb@1f03400/pmic@3a3/regulators/dcdc3";
		reg_dcdc4 = "/soc/rsb@1f03400/pmic@3a3/regulators/dcdc4";
		reg_dcdc5 = "/soc/rsb@1f03400/pmic@3a3/regulators/dcdc5";
		reg_dcdc6 = "/soc/rsb@1f03400/pmic@3a3/regulators/dcdc6";
		reg_dldo1 = "/soc/rsb@1f03400/pmic@3a3/regulators/dldo1";
		reg_dldo2 = "/soc/rsb@1f03400/pmic@3a3/regulators/dldo2";
		reg_dldo3 = "/soc/rsb@1f03400/pmic@3a3/regulators/dldo3";
		reg_dldo4 = "/soc/rsb@1f03400/pmic@3a3/regulators/dldo4";
		reg_eldo1 = "/soc/rsb@1f03400/pmic@3a3/regulators/eldo1";
		reg_eldo2 = "/soc/rsb@1f03400/pmic@3a3/regulators/eldo2";
		reg_eldo3 = "/soc/rsb@1f03400/pmic@3a3/regulators/eldo3";
		reg_fldo1 = "/soc/rsb@1f03400/pmic@3a3/regulators/fldo1";
		reg_fldo2 = "/soc/rsb@1f03400/pmic@3a3/regulators/fldo2";
		reg_ldo_io0 = "/soc/rsb@1f03400/pmic@3a3/regulators/ldo-io0";
		reg_ldo_io1 = "/soc/rsb@1f03400/pmic@3a3/regulators/ldo-io1";
		reg_rtc_ldo = "/soc/rsb@1f03400/pmic@3a3/regulators/rtc-ldo";
		reg_drivevbus = "/soc/rsb@1f03400/pmic@3a3/regulators/drivevbus";
		usb_power_supply = "/soc/rsb@1f03400/pmic@3a3/usb-power-supply";
		wdt0 = "/soc/watchdog@1c20ca0";
		cpu0_opp_table = "/opp_table0";
		hdmi_con_in = "/hdmi-connector/port/endpoint";
		wifi_pwrseq = "/wifi_pwrseq";
	};
};
